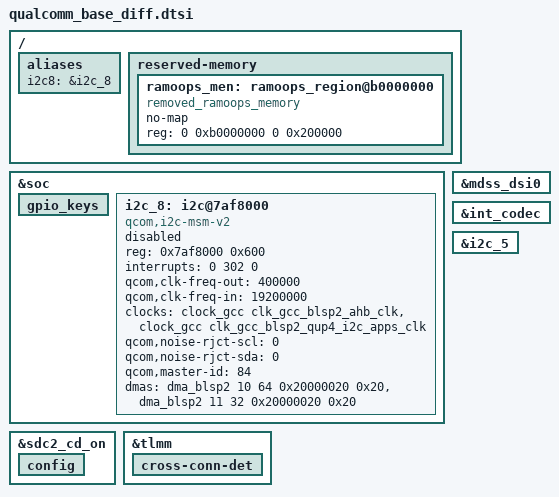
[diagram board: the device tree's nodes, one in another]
/*
 * this file is ued to change qualcomm dtsi which can't be changed by overlay
 * such as /delete-node/ /delete-property/ and alises
 */

&soc {
	gpio_keys {
		/delete-node/ camera_focus;
		/delete-node/ camera_snapshot;
	};

};

&sdc2_cd_on {
	config {
		/delete-property/ bias-pull-up;
	};
};

/ {
	aliases {
		i2c8 = &i2c_8;
	};
};


&soc {
	i2c_8: i2c@7af8000 { /* BLSP2 QUP4 */
		compatible = "qcom,i2c-msm-v2";
		#address-cells = <1>;
		#size-cells = <0>;
		reg-names = "qup_phys_addr";
		reg = <0x7af8000 0x600>;
		interrupt-names = "qup_irq";
		interrupts = <0 302 0>;
		qcom,clk-freq-out = <400000>;
		qcom,clk-freq-in  = <19200000>;
		clock-names = "iface_clk", "core_clk";
		clocks = <&clock_gcc clk_gcc_blsp2_ahb_clk>,
			<&clock_gcc clk_gcc_blsp2_qup4_i2c_apps_clk>;

		qcom,noise-rjct-scl = <0>;
		qcom,noise-rjct-sda = <0>;
		qcom,master-id = <84>;
		dmas = <&dma_blsp2 10 64 0x20000020 0x20>,
			<&dma_blsp2 11 32 0x20000020 0x20>;
		dma-names = "tx", "rx";
		status = "disabled";
	};
};

&mdss_dsi0 {
	/delete-property/ qcom,platform-bklight-en-gpio;
};

&int_codec {
	/delete-property/ asoc-wsa-codec-names;
	/delete-property/ asoc-wsa-codec-prefixes;

	/delete-property/ msm-vdd-wsa-switch-supply;
	/delete-property/ qcom,msm-vdd-wsa-switch-voltage;
	/delete-property/ qcom,msm-vdd-wsa-switch-current;
	/delete-property/ qcom,cdc-us-euro-gpios;
	/delete-property/ qcom,cdc-us-eu-gpios;
};

/ {
	reserved-memory {
		#address-cells = <2>;
		#size-cells = <2>;
		ranges;

		/*add by ZTE_BOOT*/
		ramoops_men: ramoops_region@b0000000 {
			compatible = "removed_ramoops_memory";
			no-map;
			reg = <0 0xb0000000 0 0x200000>;
		};
	};
};

&i2c_5 {
	/delete-node/ nq@28;
};

&tlmm {
	cross-conn-det {
		/delete-node/ cross_conn_det_act;
		/delete-node/ cross_conn_det_sus;
	};
};
